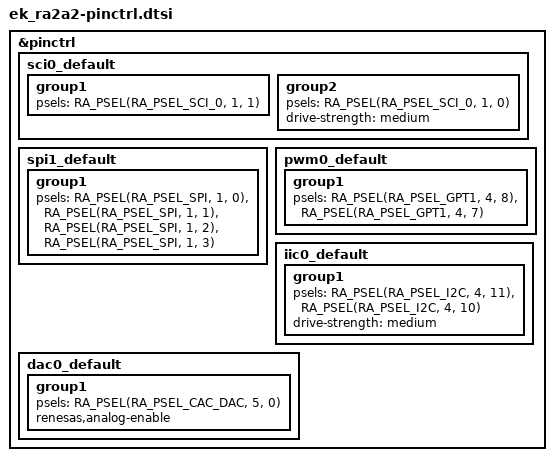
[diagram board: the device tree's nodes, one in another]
/*
 * Copyright (c) 2025 Renesas Electronics Corporation and/or its affiliates
 *
 * SPDX-License-Identifier: Apache-2.0
 */

&pinctrl {
	sci0_default: sci0_default {
		group1 {
			/* rx */
			psels = <RA_PSEL(RA_PSEL_SCI_0, 1, 1)>;
		};
		group2 {
			/* tx */
			psels = <RA_PSEL(RA_PSEL_SCI_0, 1, 0)>;
			drive-strength = "medium";
		};
	};

	spi1_default: spi1_default {
		group1 {
			/* MISO MOSI RSPCK SSL */
			psels = <RA_PSEL(RA_PSEL_SPI, 1, 0)>,
			<RA_PSEL(RA_PSEL_SPI, 1, 1)>,
			<RA_PSEL(RA_PSEL_SPI, 1, 2)>,
			<RA_PSEL(RA_PSEL_SPI, 1, 3)>;
		};
	};

	pwm0_default: pwm0_default {
		group1 {
			/* GTIOC0A GTIOC0B */
			psels = <RA_PSEL(RA_PSEL_GPT1, 4, 8)>,
				<RA_PSEL(RA_PSEL_GPT1, 4, 7)>;
		};
	};

	iic0_default: iic0_default {
		group1 {
			/* SCL0 SDA0 */
			psels = <RA_PSEL(RA_PSEL_I2C, 4, 11)>,
			<RA_PSEL(RA_PSEL_I2C, 4, 10)>;
			drive-strength = "medium";
		};
	};

	dac0_default: dac0_default {
		group1 {
			/* output */
			psels = <RA_PSEL(RA_PSEL_CAC_DAC, 5, 0)>;
			renesas,analog-enable;
		};
	};
};
